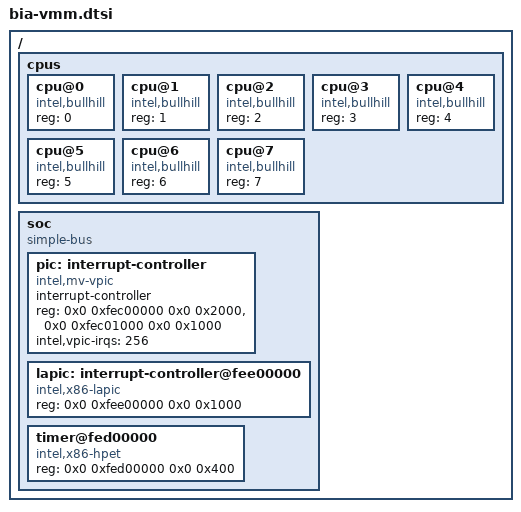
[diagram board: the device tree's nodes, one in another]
/* BIA core */
/ {
	cpus {
		#address-cells = <1>;
		#size-cells = <0>;

		cpu@0 {
			device_type = "cpu";
			compatible = "intel,bullhill";
			reg = <0>;
		};

		cpu@1 {
			device_type = "cpu";
			compatible = "intel,bullhill";
			reg = <1>;
		};

		cpu@2 {
			device_type = "cpu";
			compatible = "intel,bullhill";
			reg = <2>;
		};

		cpu@3 {
			device_type = "cpu";
			compatible = "intel,bullhill";
			reg = <3>;
		};

		cpu@4 {
			device_type = "cpu";
			compatible = "intel,bullhill";
			reg = <4>;
		};

		cpu@5 {
			device_type = "cpu";
			compatible = "intel,bullhill";
			reg = <5>;
		};

		cpu@6 {
			device_type = "cpu";
			compatible = "intel,bullhill";
			reg = <6>;
		};

		cpu@7 {
			device_type = "cpu";
			compatible = "intel,bullhill";
			reg = <7>;
		};
	};

	soc {
		#address-cells = <2>;
		#size-cells = <2>;
		compatible = "simple-bus";
		ranges;

		pic: interrupt-controller {
			compatible = "intel,mv-vpic";
			#interrupt-cells = <2>;
			interrupt-controller;
			reg = <0x0 0xfec00000 0x0 0x2000>,
				<0x0 0xfec01000 0x0 0x1000>;
			intel,vpic-irqs = < 256 >;
		};

		lapic:interrupt-controller@fee00000{
			compatible = "intel,x86-lapic";
			reg = <0x0 0xfee00000 0x0 0x1000>;
		};

		timer@fed00000 {
			compatible = "intel,x86-hpet";
			reg = <0x0 0xfed00000 0x0 0x400>;
		};
	};
};

